# ATmega128RFA1 register map
Vendor: Atmel; File version: 1.0
CPU: other r0p0, little endian, no MPU, no FPU, 4 interrupt priority bits
Registers are 8-bit, read-write, reset 0x0 unless marked. A register's access mark holds for its fields unless they carry their own. Offsets are from the block's base; [hi:lo] are bit positions; 'fields as' and 'values as' point back to an identical list.

## PORTE — I/O Port
Base 0x0080002C
0x00 PINE — Port E Input Pins Address
0x01 DDRE — Port E Data Direction Register
0x02 PORTE — Port E Data Register

## PORTF — I/O Port
Base 0x0080002F
0x00 PINF — Port F Input Pins Address
0x01 DDRF — Port F Data Direction Register
0x02 PORTF — Port F Data Register

## PORTG — I/O Port
Base 0x00800032
0x00 PING — Port G Input Pins Address
0x01 DDRG — Port G Data Direction Register
0x02 PORTG — Port G Data Register

## PWRCTRL — Power Controller
Base 0x00800055
0x00 MCUCR — MCU Control Register
  [4] PUD — Pull-up Disable
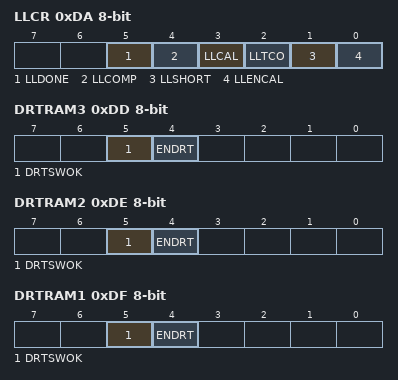
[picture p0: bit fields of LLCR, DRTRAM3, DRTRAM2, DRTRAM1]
0xDA LLCR — Low Leakage Voltage Regulator Control Register
  [5] LLDONE — Calibration Done
  [4] LLCOMP — Comparator Output
  [3] LLCAL — Calibration Active
  [2] LLTCO — Temperature Coefficient of Current Source
  [1] LLSHORT — Short Lower Calibration Circuit
  [0] LLENCAL — Enable Automatic Calibration
0xDB LLDRL — Low Leakage Voltage Regulator Data Register (Low-Byte)
  [3:0] LLDRL — Low-Byte Data Register Bits
    0=CALIBRATION_LIMIT_FOR_FAST_PROCESS_CORNER_HIGH_OUTPUT_VOLTAGE; 8=CALIBRATION_LIMIT_FOR_SLOW_PROCESS_CORNER_LOW_OUTPUT_VOLTAGE
0xDC LLDRH — Low Leakage Voltage Regulator Data Register (High-Byte)
  [4:0] LLDRH — High-Byte Data Register Bits
    0=CALIBRATION_LIMIT_FOR_FAST_PROCESS_CORNER_HIGH_OUTPUT_VOLTAGE; 16=CALIBRATION_LIMIT_FOR_SLOW_PROCESS_CORNER_LOW_OUTPUT_VOLTAGE
0xDD DRTRAM3 — Data Retention Configuration Register of SRAM 3
  [5] DRTSWOK — DRT Switch OK
  [4] ENDRT — Enable SRAM Data Retention
0xDE DRTRAM2 — Data Retention Configuration Register of SRAM 2
  [5] DRTSWOK — DRT Switch OK
  [4] ENDRT — Enable SRAM Data Retention
0xDF DRTRAM1 — Data Retention Configuration Register of SRAM 1
  [5] DRTSWOK — DRT Switch OK
  [4] ENDRT — Enable SRAM Data Retention
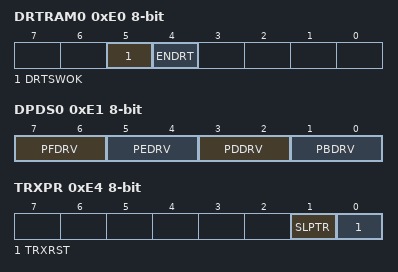
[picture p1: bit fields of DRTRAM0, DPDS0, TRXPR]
0xE0 DRTRAM0 — Data Retention Configuration Register of SRAM 0
  [5] DRTSWOK — DRT Switch OK
  [4] ENDRT — Enable SRAM Data Retention
0xE1 DPDS0 — Port Driver Strength Register 0
  [all] fields
    0=PAD_IO_2MA (2 mA); 1=PAD_IO_4MA (4 mA); 2=PAD_IO_6MA (6 mA); 3=PAD_IO_8MA (8 mA)
  [7:6] PFDRV — Driver Strength Port F
  [5:4] PEDRV — Driver Strength Port E
  [3:2] PDDRV — Driver Strength Port D
  [1:0] PBDRV — Driver Strength Port B
0xE2 DPDS1 — Port Driver Strength Register 1
  [1:0] PGDRV — Driver Strength Port G
    values as the fields of DPDS0
0xE4 TRXPR — Transceiver Pin Register
  [1] SLPTR — Multi-purpose Transceiver Control Bit
  [0] TRXRST — Force Transceiver Reset

## SPI — Serial Peripheral Interface
Base 0x0080004C
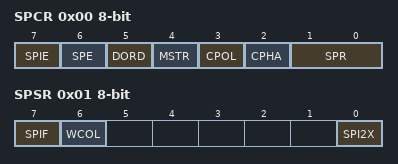
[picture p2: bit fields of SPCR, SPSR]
0x00 SPCR — SPI Control Register
  [7] SPIE — SPI Interrupt Enable
  [6] SPE — SPI Enable
  [5] DORD — Data Order
  [4] MSTR — Master/Slave Select
  [3] CPOL — Clock polarity
    0=RISING_LEADING_EDGE_FALLING_TRAILING_EDGE; 1=FALLING_LEADING_EGDE_RISING_TRAILING_EDGE (Falling (Leading Edge), Rising (Trailing Edge))
  [2] CPHA — Clock Phase
    0=SAMPLE_LEADING_EDGE_SETUP_TRAILING_EDGE; 1=SETUP_LEADING_EDGE_SAMPLE_TRAILING_EDGE
  [1:0] SPR — SPI Clock Rate Select 1 and 0
    0=FOSC_4; 1=FOSC_16; 3=FOSC_128
0x01 SPSR — SPI Status Register (read-only for debugger)
  [7] SPIF — SPI Interrupt Flag
  [6] WCOL — Write Collision Flag
  [0] SPI2X — Double SPI Speed Bit
0x02 SPDR — SPI Data Register (write-only for debugger)

## SYMCNT — MAC Symbol Counter
Base 0x008000DC
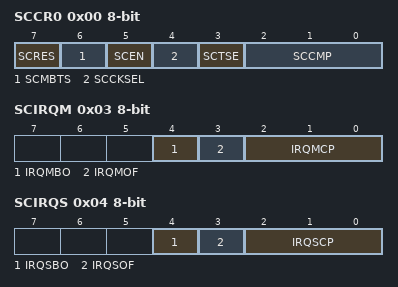
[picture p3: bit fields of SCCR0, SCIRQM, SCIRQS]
0x00 SCCR0 — Symbol Counter Control Register 0
  [7] SCRES — Symbol Counter Synchronization
  [6] SCMBTS — Manual Beacon Timestamp
  [5] SCEN — Symbol Counter enable
  [4] SCCKSEL — Symbol Counter Clock Source select
  [3] SCTSE — Symbol Counter Automatic Timestamping enable
  [2:0] SCCMP — Symbol Counter Compare Unit 3 Mode select
0x01 SCCR1 — Symbol Counter Control Register 1
  [0] SCENBO — Backoff Slot Counter enable
0x02 SCSR — Symbol Counter Status Register (read-only for debugger)
  [0] SCBSY — Symbol Counter busy
0x03 SCIRQM — Symbol Counter Interrupt Mask Register
  [4] IRQMBO — Backoff Slot Counter IRQ enable
  [3] IRQMOF — Symbol Counter Overflow IRQ enable
  [2:0] IRQMCP — Symbol Counter Compare Match 3 IRQ enable
0x04 SCIRQS — Symbol Counter Interrupt Status Register
  [4] IRQSBO — Backoff Slot Counter IRQ
  [3] IRQSOF — Symbol Counter Overflow IRQ
  [2:0] IRQSCP — Compare Unit 3 Compare Match IRQ
0x05 SCCNTLL — Symbol Counter Register LL-Byte
0x06 SCCNTLH — Symbol Counter Register LH-Byte
0x07 SCCNTHL — Symbol Counter Register HL-Byte
0x08 SCCNTHH — Symbol Counter Register HH-Byte
0x09 SCBTSRLL — Symbol Counter Beacon Timestamp Register LL-Byte
0x0A SCBTSRLH — Symbol Counter Beacon Timestamp Register LH-Byte
0x0B SCBTSRHL — Symbol Counter Beacon Timestamp Register HL-Byte
0x0C SCBTSRHH — Symbol Counter Beacon Timestamp Register HH-Byte
0x0D SCTSRLL — Symbol Counter Frame Timestamp Register LL-Byte (read-only for debugger)
  [7:0] SCTSRLL — Symbol Counter Frame Timestamp Register LL-Byte
0x0E SCTSRLH — Symbol Counter Frame Timestamp Register LH-Byte (read-only for debugger)
  [7:0] SCTSRLH — Symbol Counter Frame Timestamp Register LH-Byte
0x0F SCTSRHL — Symbol Counter Frame Timestamp Register HL-Byte (read-only for debugger)
  [7:0] SCTSRHL — Symbol Counter Frame Timestamp Register HL-Byte
0x10 SCTSRHH — Symbol Counter Frame Timestamp Register HH-Byte (read-only for debugger)
  [7:0] SCTSRHH — Symbol Counter Frame Timestamp Register HH-Byte
0x11 SCOCR3LL — Symbol Counter Output Compare Register 3 LL-Byte
0x12 SCOCR3LH — Symbol Counter Output Compare Register 3 LH-Byte
0x13 SCOCR3HL — Symbol Counter Output Compare Register 3 HL-Byte
0x14 SCOCR3HH — Symbol Counter Output Compare Register 3 HH-Byte
0x15 SCOCR2LL — Symbol Counter Output Compare Register 2 LL-Byte
0x16 SCOCR2LH — Symbol Counter Output Compare Register 2 LH-Byte
0x17 SCOCR2HL — Symbol Counter Output Compare Register 2 HL-Byte
0x18 SCOCR2HH — Symbol Counter Output Compare Register 2 HH-Byte
0x19 SCOCR1LL — Symbol Counter Output Compare Register 1 LL-Byte
0x1A SCOCR1LH — Symbol Counter Output Compare Register 1 LH-Byte
0x1B SCOCR1HL — Symbol Counter Output Compare Register 1 HL-Byte
0x1C SCOCR1HH — Symbol Counter Output Compare Register 1 HH-Byte
